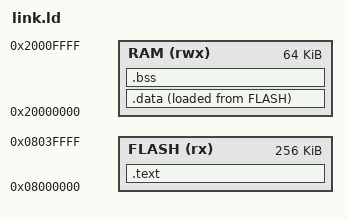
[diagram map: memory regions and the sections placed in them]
/*
 * Simple linker script for ARM Cortex-M test binaries
 * Mimics STM32 memory layout
 */

MEMORY
{
    FLASH (rx)  : ORIGIN = 0x08000000, LENGTH = 256K
    RAM (rwx)   : ORIGIN = 0x20000000, LENGTH = 64K
}

SECTIONS
{
    .text : {
        KEEP(*(.isr_vector))
        *(.text*)
        *(.rodata*)
    } > FLASH

    .data : {
        _sdata = .;
        *(.data*)
        _edata = .;
    } > RAM AT > FLASH

    .bss : {
        _sbss = .;
        *(.bss*)
        *(COMMON)
        _ebss = .;
    } > RAM

    /DISCARD/ : {
        *(.ARM.exidx*)
        *(.eh_frame*)
    }
}
